# LPC844 register map
Vendor: nxp.com; File version: 1.0
CPU: CM0PLUS r0p0, little endian, no MPU, no FPU, VTOR, 2 interrupt priority bits
Registers are 32-bit, read-write, reset 0x0 unless marked. A register's access mark holds for its fields unless they carry their own. Offsets are from the block's base; [hi:lo] are bit positions; {n}, {i} and the like mark numbered series; 'fields as' and 'values as' point back to an identical list.

## IOCON — LPC84x I/O pin configuration (IOCON)
Base 0x40044000
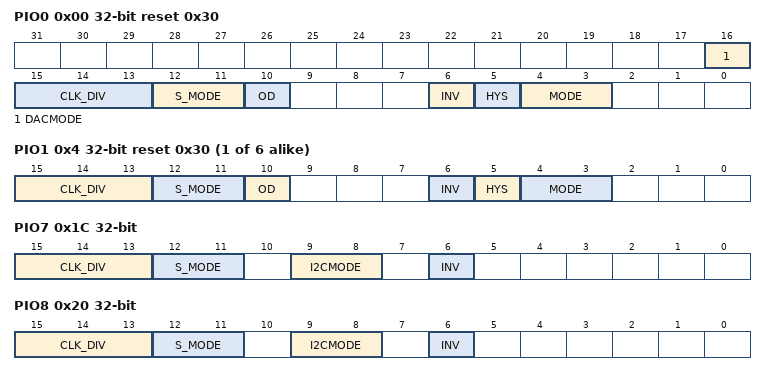
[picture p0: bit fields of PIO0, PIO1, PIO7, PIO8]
0x00 PIO0 reset 0x30 — Digital I/O control for port 0 pins PIO0
  [16] DACMODE — DAC mode enable.
    0=DISABLE; 1=ENABLE
  [15:13] CLK_DIV — Select peripheral clock divider for input filter sampling clock. Value 0x7 is reserved.
    {v}=IOCONCLKDIV{v} (v=0..6)
  [12:11] S_MODE — Digital filter sample mode.
    0=Bypass input filter; 1=1 clock cycle. Input pulses shorter than one filter clock are rejected.; 2=2 clock cycles. Input pulses shorter than two filter clocks are rejected.; 3=3 clock cycles. Input pulses shorter than three filter clocks are rejected.
  [10] OD — Open-drain mode.
    0=DISABLE; 1=ENABLED (Open-drain mode enabled. Remark: This is not a true open-drain mode.)
  [6] INV — Invert input
    0=NOT_INVERTED (Input not inverted (HIGH on pin reads as 1; LOW on pin reads as 0).); 1=INVERTED (Input inverted (HIGH on pin reads as 0, LOW on pin reads as 1).)
  [5] HYS — Hysteresis.
    0=DISABLE; 1=ENABLE
  [4:3] MODE — Selects function mode (on-chip pull-up/pull-down resistor control).
    0=INACTIVE (Inactive. Inactive (no pull-down/pull-up resistor enabled).); 1=PULL_DOWN (Pull-down. Pull-down resistor enabled.); 2=PULL_UP (Pull-up. Pull-up resistor enabled.); 3=REPEATER (Repeater. Repeater mode.)
{0x0+4i} PIO{i} reset 0x30 (i=1..6) — Digital I/O control for port 0 pins PIO{i}
  [15:13] CLK_DIV — Select peripheral clock divider for input filter sampling clock. Value 0x7 is reserved.
    {v}=IOCONCLKDIV{v} (v=0..6)
  [12:11] S_MODE — Digital filter sample mode.
    values as PIO0.S_MODE
  [10] OD — Open-drain mode.
    values as PIO0.OD
  [6] INV — Invert input
    values as PIO0.INV
  [5] HYS — Hysteresis.
    0=DISABLE; 1=ENABLE
  [4:3] MODE — Selects function mode (on-chip pull-up/pull-down resistor control).
    values as PIO0.MODE
0x1C PIO7 — Digital I/O control for port 0 pins PIO7
  [15:13] CLK_DIV — Select peripheral clock divider for input filter sampling clock. Value 0x7 is reserved.
    {v}=IOCONCLKDIV{v} (v=0..6)
  [12:11] S_MODE — Digital filter sample mode.
    values as PIO0.S_MODE
  [9:8] I2CMODE — Selects I2C mode.
    0=STANDARAD_I2C (Standard mode/ Fast-mode I2C.); 1=Standard GPIO functionality. Requires external pull-up for GPIO output function.; 2=FAST_PLUS_I2C (Fast-mode Plus I2C)
  [6] INV — Invert input
    values as PIO0.INV
0x20 PIO8 — Digital I/O control for port 0 pins PIO8
  fields as PIO7
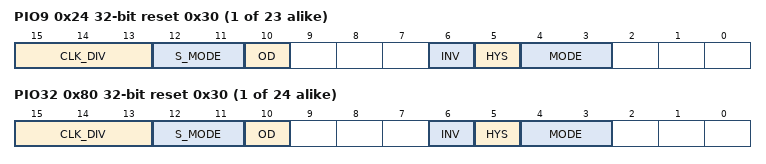
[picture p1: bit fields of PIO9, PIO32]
{0x0+4i} PIO{i} reset 0x30 (i=9..31) — Digital I/O control for port 0 pins PIO{i}
  fields as PIO1
{0x0+4i} PIO{i} reset 0x30 (i=32..55) — Digital I/O control for port 1 pins PIO{i}
  fields as PIO1

## CRC — LPC5411x CRC engine
Base 0x50000000
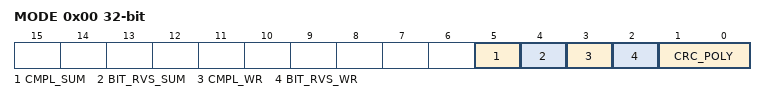
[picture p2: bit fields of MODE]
0x00 MODE — CRC mode register
  [5] CMPL_SUM — CRC sum complement: 1 = 1's complement for CRC_SUM 0 = No 1's complement for CRC_SUM
  [4] BIT_RVS_SUM — CRC sum bit order: 1 = Bit order reverse for CRC_SUM 0 = No bit order reverse for CRC_SUM
  [3] CMPL_WR — Data complement: 1 = 1's complement for CRC_WR_DATA 0 = No 1's complement for CRC_WR_DATA
  [2] BIT_RVS_WR — Data bit order: 1 = Bit order reverse for CRC_WR_DATA (per byte) 0 = No bit order reverse for CRC_WR_DATA (per byte)
  [1:0] CRC_POLY — CRC polynomial: 1X = CRC-32 polynomial 01 = CRC-16 polynomial 00 = CRC-CCITT polynomial
0x04 SEED reset 0xFFFF — CRC seed register
  [31:0] CRC_SEED — A write access to this register will load CRC seed value to CRC_SUM register with selected bit order and 1's complement pre-processes. A write access to this register will overrule the CRC calculation in progresses.
0x08 SUM ro reset 0xFFFF (SUM_WR_DATA view) — CRC checksum register
  [31:0] CRC_SUM — The most recent CRC sum can be read through this register with selected bit order and 1's complement post-processes.
0x08 WR_DATA wo reset not defined (SUM_WR_DATA view) — CRC data register
  [31:0] CRC_WR_DATA — Data written to this register will be taken to perform CRC calculation with selected bit order and 1's complement pre-process. Any write size 8, 16 or 32-bit are allowed and accept back-to-back transactions.
